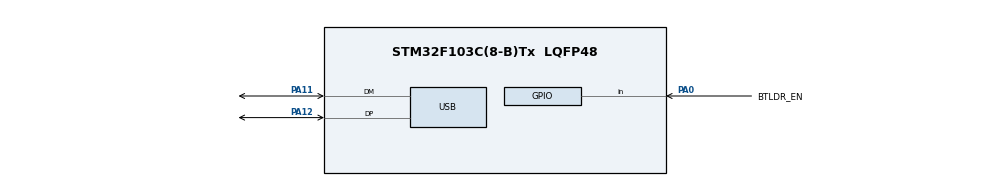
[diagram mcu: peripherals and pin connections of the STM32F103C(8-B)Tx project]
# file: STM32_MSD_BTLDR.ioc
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Mcu.Family=STM32F1
Mcu.Name=STM32F103C(8-B)Tx
Mcu.Package=LQFP48
NVIC.PriorityGroup=NVIC_PRIORITYGROUP_4
NVIC.USB_LP_CAN1_RX0_IRQn=true\:0\:0\:false\:false\:true\:false\:true
PA0-WKUP.GPIO_Label=BTLDR_EN
PA0-WKUP.GPIO_PuPd=GPIO_PULLUP
PA0-WKUP.Signal=GPIO_Input
PA11.Mode=Device
PA11.Signal=USB_DM
PA12.Mode=Device
PA12.Signal=USB_DP
PA13.Mode=Serial_Wire
PA13.Signal=SYS_JTMS-SWDIO
PA14.Mode=Serial_Wire
PA14.Signal=SYS_JTCK-SWCLK
PD0-OSC_IN.Mode=HSE-External-Oscillator
PD0-OSC_IN.Signal=RCC_OSC_IN
PD1-OSC_OUT.Mode=HSE-External-Oscillator
PD1-OSC_OUT.Signal=RCC_OSC_OUT
ProjectManager.HeapSize=0x200
ProjectManager.StackSize=0x400
ProjectManager.TargetToolchain=MDK-ARM V5
RCC.AHBFreq_Value=72000000
RCC.APB1CLKDivider=RCC_HCLK_DIV2
RCC.APB1Freq_Value=36000000
RCC.APB1TimFreq_Value=72000000
RCC.APB2CLKDivider=RCC_HCLK_DIV2
RCC.APB2Freq_Value=36000000
RCC.APB2TimFreq_Value=72000000
RCC.HCLKFreq_Value=72000000
RCC.PLLMUL=RCC_PLL_MUL9
RCC.SYSCLKFreq_VALUE=72000000
RCC.SYSCLKSource=RCC_SYSCLKSOURCE_PLLCLK
RCC.USBFreq_Value=48000000
RCC.USBPrescaler=RCC_USBCLKSOURCE_PLL_DIV1_5
USB_DEVICE.CLASS_NAME_FS=MSC
USB_DEVICE.VirtualMode=Msc
USB_DEVICE.VirtualModeFS=Msc_FS
VP_USB_DEVICE_VS_USB_DEVICE_MSC_FS.Mode=MSC_FS
board=custom

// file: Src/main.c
/*************************************************************************************
# Released under MIT License

Copyright (c) 2020 SF Yip (yipxxx@gmail.com)

Permission is hereby granted, free of charge, to any person obtaining a copy of this software and associated documentation files (the "Software"), to deal in the Software without restriction, including without limitation the rights to use, copy, modify, merge, publish, distribute, sublicense, and/or sell copies of the Software, and to permit persons to whom the Software is furnished to do so, subject to the following conditions:

The above copyright notice and this permission notice shall be included in all copies or substantial portions of the Software.

THE SOFTWARE IS PROVIDED "AS IS", WITHOUT WARRANTY OF ANY KIND, EXPRESS OR IMPLIED, INCLUDING BUT NOT LIMITED TO THE WARRANTIES OF MERCHANTABILITY, FITNESS FOR A PARTICULAR PURPOSE AND NONINFRINGEMENT. IN NO EVENT SHALL THE AUTHORS OR COPYRIGHT HOLDERS BE LIABLE FOR ANY CLAIM, DAMAGES OR OTHER LIABILITY, WHETHER IN AN ACTION OF CONTRACT, TORT OR OTHERWISE, ARISING FROM, OUT OF OR IN CONNECTION WITH THE SOFTWARE OR THE USE OR OTHER DEALINGS IN THE SOFTWARE.
**************************************************************************************/

/* USER CODE BEGIN Header */
/**
  ******************************************************************************
  * @file           : main.c
  * @brief          : Main program body
  ******************************************************************************
  * @attention
  *
  * <h2><center>&copy; Copyright (c) 2020 STMicroelectronics.
  * All rights reserved.</center></h2>
  *
  * This software component is licensed by ST under Ultimate Liberty license
  * SLA0044, the "License"; You may not use this file except in compliance with
  * the License. You may obtain a copy of the License at:
  *                             www.st.com/SLA0044
  *
  ******************************************************************************
  */
/* USER CODE END Header */
#include "main.h"
#include "usb_device.h"

/* USER CODE BEGIN Includes */
#include <stdint.h>
#include <stdbool.h>
#include "btldr_config.h"
#include "crypt.h"
#include "ihex_parser.h"
#include "crc.h"

/* USER CODE END Includes */

void SystemClock_Config(void);
static void MX_GPIO_Init(void);

/* USER CODE BEGIN 0 */
#if (BTLDR_ACT_NoAppExist > 0u)
bool is_appcode_exist(void)
{
  uint32_t *mem = (uint32_t*)APP_ADDR;

  if ((mem[0] == 0x00000000 || mem[0] == 0xFFFFFFFF) && \
      (mem[1] == 0x00000000 || mem[1] == 0xFFFFFFFF) && \
      (mem[2] == 0x00000000 || mem[2] == 0xFFFFFFFF) && \
      (mem[3] == 0x00000000 || mem[3] == 0xFFFFFFFF))
  {
    return false;
  }
  else
  {
    return true;
  }
}
#endif

#if (BTLDR_ACT_CksNotVld > 0u)
bool app_cks_valid(void)
{
	uint32_t app_crc32 = 0;

	/* calculate CRC32 checksum from start of main application until CRC32 location */
	app_crc32 = crc32_calculate((const uint8_t *)APP_ADDR, (CRC_ADDR-APP_ADDR));

	/* compare self calculated CRC32 with CRC32 stored in flash */
	return (app_crc32 == *((uint32_t*)(CRC_ADDR)));
}
#endif

#if (BTLDR_ACT_ButtonPress > 0u)
bool is_button_down(void)
{
    return (!LL_GPIO_IsInputPinSet(BTLDR_EN_GPIO_Port, BTLDR_EN_Pin) );
}
#endif

#if (BTLDR_ACT_BootkeyDet > 0u)

volatile __attribute__((section("._bootkey_section.btldr_act_req_key"))) uint32_t btldr_act_req_key;

bool bootkey_detected(void){
    return(btldr_act_req_key == BOOTKEY);
}
#endif

extern PCD_HandleTypeDef hpcd_USB_FS;

void SystemReset(void){
    LL_mDelay(500);

    HAL_PCD_Stop(&hpcd_USB_FS);

    /* Pull USB D+ PIN to GND so USB Host detects device disconnect */
    LL_GPIO_SetPinMode(GPIOA,LL_GPIO_PIN_12, LL_GPIO_MODE_OUTPUT);
    LL_GPIO_SetPinSpeed(GPIOA, LL_GPIO_PIN_12, LL_GPIO_SPEED_FREQ_LOW);
    LL_GPIO_SetPinOutputType(GPIOA,LL_GPIO_PIN_12, LL_GPIO_OUTPUT_PUSHPULL);
    LL_GPIO_ResetOutputPin(GPIOA, LL_GPIO_PIN_12);

    LL_mDelay(1000);

    NVIC_SystemReset();
}

/* USER CODE END 0 */

int main(void)
{
  /* USER CODE BEGIN 1 */
  static uint32_t jump_addr;

  /* USER CODE END 1 */

  /* MCU Configuration--------------------------------------------------------*/

  /* Reset of all peripherals, Initializes the Flash interface and the Systick. */
  HAL_Init();

  /* Configure the system clock */
  SystemClock_Config();

  /* Initialize all configured peripherals */
  MX_GPIO_Init();

  /* USER CODE BEGIN 2 */

 if(	/* Check for configured activation options */
    #if (BTLDR_ACT_NoAppExist > 0u)
      !is_appcode_exist()
    #endif
    #if (BTLDR_ACT_ButtonPress > 0u)
      || is_button_down()
    #endif
    #if (BTLDR_ACT_CksNotVld > 0u)
      || !app_cks_valid()
    #endif
    #if (BTLDR_ACT_BootkeyDet > 0u)
      || bootkey_detected()
    #endif
	 )
  {
#if(CONFIG_SUPPORT_CRYPT_MODE > 0u)
    crypt_init();
#endif
    MX_USB_DEVICE_Init();
    while(1)
    {
#if (CONFIG_SOFT_RESET_AFTER_IHEX_EOF > 0u)
      if(ihex_is_eof()) {
        #if (BTLDR_ACT_BootkeyDet > 0u)
         btldr_act_req_key = 0;
        #endif
         SystemReset();
      }
#endif
    }
  }
  else
  {
    // Jump to the app code
	jump_addr = *((__IO uint32_t*)(APP_ADDR+4u));
	HAL_DeInit();

	// Disable all interrupts
	NVIC->ICER[0] = 0xFFFFFFFF;
	NVIC->ICER[1] = 0xFFFFFFFF;
	NVIC->ICER[2] = 0xFFFFFFFF;

	NVIC->ICPR[0] = 0xFFFFFFFF;
	NVIC->ICPR[1] = 0xFFFFFFFF;
	NVIC->ICPR[2] = 0xFFFFFFFF;

	/* deactivate SysTick */
	SysTick->CTRL = 0;

	/* Change the main stack pointer. */
	SCB->VTOR = APP_ADDR;
	__set_MSP((*(__IO uint32_t*)APP_ADDR));

	((void (*) (void)) (jump_addr)) ();
  }

  /* USER CODE END 2 */

  /* Infinite loop */
  while (1)
  {

  }
}

void SystemClock_Config(void)
{
  LL_FLASH_SetLatency(LL_FLASH_LATENCY_2);
  while(LL_FLASH_GetLatency()!= LL_FLASH_LATENCY_2)
  {
  }
  LL_RCC_HSE_Enable();

   /* Wait till HSE is ready */
  while(LL_RCC_HSE_IsReady() != 1)
  {

  }
  LL_RCC_PLL_ConfigDomain_SYS(LL_RCC_PLLSOURCE_HSE_DIV_1, LL_RCC_PLL_MUL_9);
  LL_RCC_PLL_Enable();

   /* Wait till PLL is ready */
  while(LL_RCC_PLL_IsReady() != 1)
  {

  }
  LL_RCC_SetAHBPrescaler(LL_RCC_SYSCLK_DIV_1);
  LL_RCC_SetAPB1Prescaler(LL_RCC_APB1_DIV_2);
  LL_RCC_SetAPB2Prescaler(LL_RCC_APB2_DIV_2);
  LL_RCC_SetSysClkSource(LL_RCC_SYS_CLKSOURCE_PLL);

   /* Wait till System clock is ready */
  while(LL_RCC_GetSysClkSource() != LL_RCC_SYS_CLKSOURCE_STATUS_PLL)
  {

  }
  LL_SetSystemCoreClock(72000000);

   /* Update the time base */
  if (HAL_InitTick (TICK_INT_PRIORITY) != HAL_OK)
  {
    Error_Handler();
  }
  LL_RCC_SetUSBClockSource(LL_RCC_USB_CLKSOURCE_PLL_DIV_1_5);
}

static void MX_GPIO_Init(void)
{
  LL_GPIO_InitTypeDef GPIO_InitStruct = {0};

  /* GPIO Ports Clock Enable */
  LL_APB2_GRP1_EnableClock(LL_APB2_GRP1_PERIPH_GPIOA);

  /**/
  GPIO_InitStruct.Pin = BTLDR_EN_Pin;
  GPIO_InitStruct.Mode = LL_GPIO_MODE_INPUT;
  GPIO_InitStruct.Pull = LL_GPIO_PULL_UP;
  LL_GPIO_Init(BTLDR_EN_GPIO_Port, &GPIO_InitStruct);

}

void Error_Handler(void)
{
}

/************************ (C) COPYRIGHT STMicroelectronics *****END OF FILE****/
